# spixfc_reva_me10 register map
Registers are access not given, no defined reset value unless marked. A register's access mark holds for its fields unless they carry their own. Offsets are from the block's base; lines under a group give offsets from that group; [hi:lo] are bit positions; {n}, {i} and the like mark numbered series; 'fields as' and 'values as' point back to an identical list; <NAME> marks a mode.

## Memory map
0x40027000 SPIXFC size 0x1000 — SPI XiP Flash Configuration Controller

## Interrupts
38 SPIXFC — SPIXFC IRQ

## SPIXFC — SPI XiP Flash Configuration Controller
Base 0x40027000
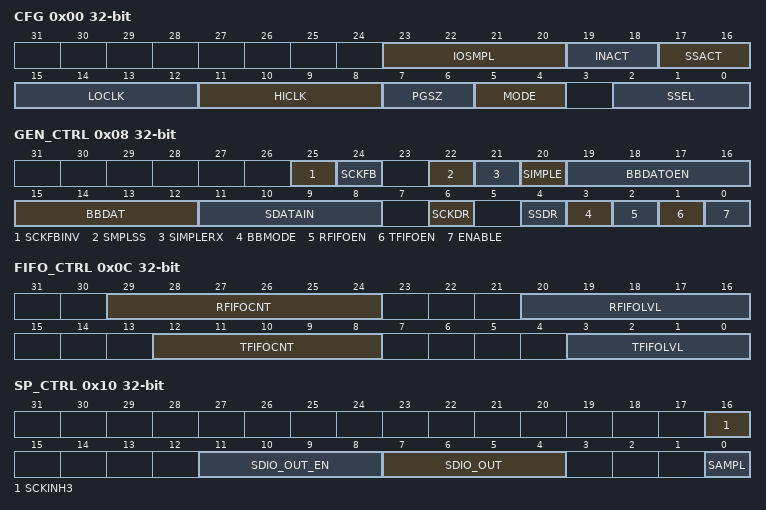
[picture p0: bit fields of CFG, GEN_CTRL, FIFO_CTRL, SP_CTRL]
0x00 CFG — Configuration Register.
  [23:20] IOSMPL — Sample Delay
    0=NODLY (No sample clock delay.); {v}={v}CLK ({v} system clocks.) (v=1..15)
  [19:18] INACT — Slaves Select Inactive Timing.
    0=4CLK (4 sytem clocks.); 1=6CLK (6 sytem clocks.); 2=8CLK (8 sytem clocks.); 3=12CLK (12 sytem clocks.)
  [17:16] SSACT — Slaves Select Activate Timing.
    0=0CLK (0 sytem clocks.); 1=2CLK (2 sytem clocks.); 2=4CLK (4 sytem clocks.); 3=8CLK (8 sytem clocks.)
  [15:12] LOCLK — SCLK low Clocks. Number of system clocks that SCLK will be low when SCLK pulses are generated. 0 correspond to 16 system clocks and, all other values defines the number of system clock taht SCLK will be held low.
    0=16CLK (16 system clocks.); {v}={v}CLK ({v} system clocks.) (v=1..15)
  [11:8] HICLK — SCLK High Clocks. Number of system clocks that SCLK will be high when SCLK pulses are generated. 0 Correspond to 16 system clocks and, all other values defines the number of system clock taht SCLK will be held high.
    values as LOCLK
  [7:6] PGSZ — Page Size.
    0=4bytes; 1=8bytes; 2=16bytes; 3=32bytes
  [5:4] MODE — Defines SPI Mode, Only valid values are 0 and 3.
    0=SPIX Mode 0. CLK Polarity = 0, CLK Phase = 0.; 3=SPIX Mode 3. CLK Polarity = 1, CLK Phase = 1.
  [2:0] SSEL — Slaves Select.
    0=Slave 0 is selected
0x04 SS_POL — SPIX Controller Slave Select Polarity Register.
  [0] SSPOL_0 — Slave Select Polarity.
    0=Active Low; 1=Active High
0x08 GEN_CTRL — SPIX Controller General Controller Register.
  [25] SCKFBINV — SCK Invert.
    0=normal; 1=invert
  [24] SCKFB — Enable SCLK Feedback Mode.
    0=dis; 1=en
  [22] SMPLSS — Simple Mode Slave Select.
    1=deassertSS (Deassert Slave select when SIMPLE = 1.)
  [21] SIMPLERX — Simple Receive Enable.
    1=initSPI (Initiate SPI transaction.)
  [20] SIMPLE — Simple Mode Enable.
    0=dis (Disable Simple Mode.); 1=en (Enable Simple Mode.)
  [19:16] BBDATOEN — Bit Bang SDIO Output Enable.
    1=SDIO0; 2=SDIO1; 4=SDIO2; 8=SDIO3
  [15:12] BBDAT
    1=SDIO0; 2=SDIO1; 4=SDIO2; 8=SDIO3
  [11:8] SDATAIN — SDIO Input Data Value.
    1=SDIO0; 2=SDIO1; 4=SDIO2; 8=SDIO3
  [6] SCKDR — SSCLK Drive and State.
    0=sck0 (SCLK is 0.); 1=sck1 (SCLK is 1.)
  [4] SSDR — This bits reflects the state of the currently selected slave select.
    0=output0 (Selected Slave select output = 0.); 1=output1 (Selected Slave select output = 1.)
  [3] BBMODE — Bit-Bang Mode.
    0=dis (Disable Bit-Bang Mode.); 1=en (Enable Bit-Bang Mode.)
  [2] RFIFOEN — Result FIFO Enable.
    0=dis (Disable Result FIFO.); 1=en (Enable Result FIFO.)
  [1] TFIFOEN — Transaction FIFO Enable.
    0=dis (Disable Transaction FIFO.); 1=en (Enable Transaction FIFO.)
  [0] ENABLE — SPI Master enable.
    0=dis (Disable SPI Master, putting a reset state.); 1=en (Enable SPI Master for processing transactions.)
0x0C FIFO_CTRL — SPIX Controller FIFO Control and Status Register.
  [29:24] RFIFOCNT — Result FIFO Used.
  [20:16] RFIFOLVL — Results FIFO Almost Full Level.
  [12:8] TFIFOCNT — Transaction FIFO Used.
  [3:0] TFIFOLVL — Transaction FIFO Almost Empty Level.
0x10 SP_CTRL — SPIX Controller Special Control Register.
  [16] SCKINH3 — SCLK Inhibit Mode3. In SPI Mode 3, some SPI flash read timing diagrams show the last SCLK going low prior to de-assertion. The default is to support this additional falling edge of clock. When this bit is set and the device is in SPI Mode 3, the SPI clock is held high while Slave Select is de-asserted. This is to support some SPI flash write timing diagrams.
    0=en (Allow trailing SCLK low pulse prior to Slave Select de-assertion.); 1=dis (Inhibit trailing SCLK low pulse prior to Slave Select de-assertion.)
  [11:8] SDIO_OUT_EN — SDIO Output Enable Sample Mode
    1=SDIO0; 2=SDIO1; 4=SDIO2; 8=SDIO3
  [7:4] SDIO_OUT — SDIO Output Value Sample Mode
    1=SDIO0; 2=SDIO1; 4=SDIO2; 8=SDIO3
  [0] SAMPL — Setting this bit to a 1 enables the ability to drive SDIO outputs prior to the assertion of Slave Select. This bit must only be set when the SPIXF bus is idle and the transaction FIFO is empty. This bit is automatically cleared by hardware after the next slave select assertion.
    0=dis (Disable sample mode.); 1=en (Enable sample mode.)
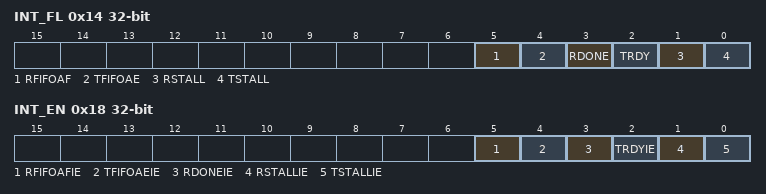
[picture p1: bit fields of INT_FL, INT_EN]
0x14 INT_FL — SPIX Controller Interrupt Status Register.
  [all] fields
    1=Clear interrupt
  [5] RFIFOAF — Results FIFO Almost Full Flag.
  [4] TFIFOAE — Transaction FIFO Almost Empty Flag.
  [3] RDONE — Results Done Interrupt Status.
  [2] TRDY — Transaction Ready Interrupt Status.
  [1] RSTALL — Results Stalled Interrupt Flag.
  [0] TSTALL — Transaction Stalled Interrupt Flag.
0x18 INT_EN — SPIX Controller Interrupt Enable Register.
  [all] fields
    0=dis (Disable Interrupt.); 1=en (Enable Interrupt.)
  [5] RFIFOAFIE — Results FIFO Almost Full Interrupt Enable.
  [4] TFIFOAEIE — Transaction FIFO Almost Empty Interrupt Enable.
  [3] RDONEIE — Results Done Interrupt Enable.
  [2] TRDYIE — Transaction Ready Interrupt Enable.
  [1] RSTALLIE — Results Stalled Interrupt Enable.
  [0] TSTALLIE — Transaction Stalled Interrupt Enable.
